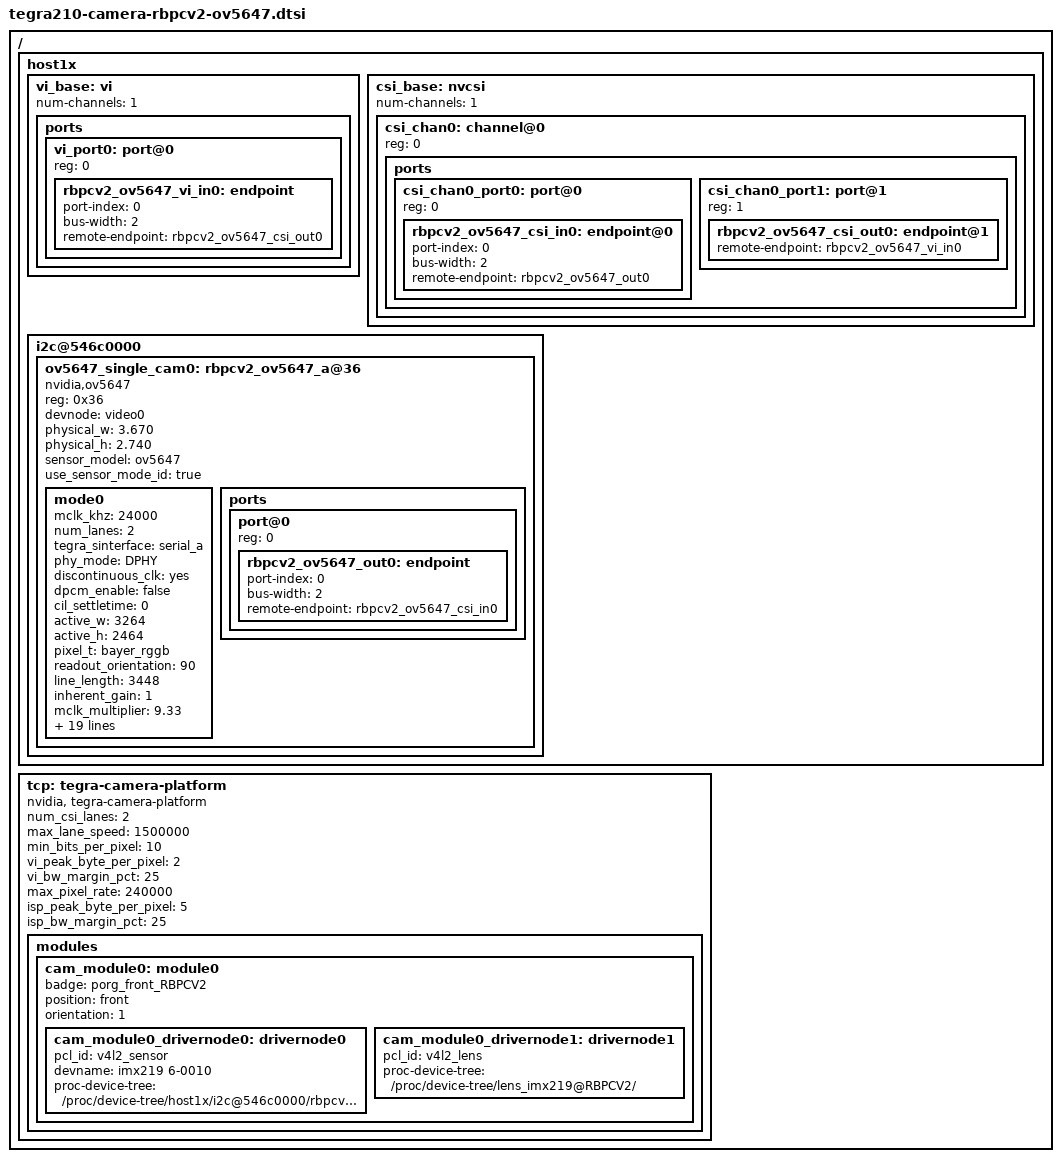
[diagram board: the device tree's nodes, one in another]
#include <dt-bindings/media/camera.h>
#include <dt-bindings/platform/t210/t210.h>

/ {
    host1x {
		vi_base: vi {
			num-channels = <1>;
			ports {
				#address-cells = <1>;
				#size-cells = <0>;
				vi_port0: port@0 {
					reg = <0>;
					rbpcv2_ov5647_vi_in0: endpoint {
						port-index = <0>;
						bus-width = <2>;
						remote-endpoint = <&rbpcv2_ov5647_csi_out0>;
					};
				};
			};
		};        
		csi_base: nvcsi {
			num-channels = <1>;
			#address-cells = <1>;
			#size-cells = <0>;
			csi_chan0: channel@0 {
				reg = <0>;
				ports {
					#address-cells = <1>;
					#size-cells = <0>;
					csi_chan0_port0: port@0 {
						reg = <0>;
						rbpcv2_ov5647_csi_in0: endpoint@0 {
							port-index = <0>;
							bus-width = <2>;
							remote-endpoint = <&rbpcv2_ov5647_out0>;
						};
					};
					csi_chan0_port1: port@1 {
						reg = <1>;
						rbpcv2_ov5647_csi_out0: endpoint@1 {
							remote-endpoint = <&rbpcv2_ov5647_vi_in0>;
						};
					};
				};
			};
		};

        i2c@546c0000 {
            ov5647_single_cam0: rbpcv2_ov5647_a@36 {
                compatible = "nvidia,ov5647";
		
                /* I2C device address */
                reg = <0x36>;

                /* V4L2 device node location */
                devnode = "video0";

                /* Physical dimensions of sensor */
                physical_w = "3.670";
                physical_h = "2.740";
                sensor_model = "ov5647";
                use_sensor_mode_id = "true";
                status = "okay";

				mode0 { /* IMX219_MODE_3264x2464_21FPS */
					mclk_khz = "24000";
					num_lanes = "2";
					tegra_sinterface = "serial_a";
					phy_mode = "DPHY";
					discontinuous_clk = "yes";
					dpcm_enable = "false";
					cil_settletime = "0";

					active_w = "3264";
					active_h = "2464";
					pixel_t = "bayer_rggb";
					readout_orientation = "90";
					line_length = "3448";
					inherent_gain = "1";
					mclk_multiplier = "9.33";
					pix_clk_hz = "182400000";

					gain_factor = "16";
					framerate_factor = "1000000";
					exposure_factor = "1000000";
					min_gain_val = "16"; /* 1.00x */
					max_gain_val = "170"; /* 10.66x */
					step_gain_val = "1";
					default_gain = "16"; /* 1.00x */
					min_hdr_ratio = "1";
					max_hdr_ratio = "1";
					min_framerate = "2000000"; /* 2.0 fps */
					max_framerate = "21000000"; /* 21.0 fps */
					step_framerate = "1";
					default_framerate = "21000000"; /* 21.0 fps */
					min_exp_time = "13"; /* us */
					max_exp_time = "683709"; /* us */
					step_exp_time = "1";
					default_exp_time = "2495"; /* us */

					embedded_metadata_height = "2";
				};				

                ports {
					#address-cells = <1>;
					#size-cells = <0>;

					port@0 {
						reg = <0>;
						rbpcv2_ov5647_out0: endpoint {
							port-index = <0>;
							bus-width = <2>;
							remote-endpoint = <&rbpcv2_ov5647_csi_in0>;
						};
					};
				};
            };
        };
    };
};


/ {
	tcp: tegra-camera-platform {
		compatible = "nvidia, tegra-camera-platform";

		/**
		* Physical settings to calculate max ISO BW
		*
		* num_csi_lanes = <>;
		* Total number of CSI lanes when all cameras are active
		*
		* max_lane_speed = <>;
		* Max lane speed in Kbit/s
		*
		* min_bits_per_pixel = <>;
		* Min bits per pixel
		*
		* vi_peak_byte_per_pixel = <>;
		* Max byte per pixel for the VI ISO case
		*
		* vi_bw_margin_pct = <>;
		* Vi bandwidth margin in percentage
		*
		* max_pixel_rate = <>;
		* Max pixel rate in Kpixel/s for the ISP ISO case
		*
		* isp_peak_byte_per_pixel = <>;
		* Max byte per pixel for the ISP ISO case
		*
		* isp_bw_margin_pct = <>;
		* Isp bandwidth margin in percentage
		*/
		num_csi_lanes = <2>;
		max_lane_speed = <1500000>;
		min_bits_per_pixel = <10>;
		vi_peak_byte_per_pixel = <2>;
		vi_bw_margin_pct = <25>;
		max_pixel_rate = <240000>;
		isp_peak_byte_per_pixel = <5>;
		isp_bw_margin_pct = <25>;

		/**
		 * The general guideline for naming badge_info contains 3 parts, and is as follows,
		 * The first part is the camera_board_id for the module; if the module is in a FFD
		 * platform, then use the platform name for this part.
		 * The second part contains the position of the module, ex. "rear" or "front".
		 * The third part contains the last 6 characters of a part number which is found
		 * in the module's specsheet from the vendor.
		 */
		modules {
			cam_module0: module0 {
				badge = "porg_front_RBPCV2";
				position = "front";
				orientation = "1";
				cam_module0_drivernode0: drivernode0 {
					pcl_id = "v4l2_sensor";
					devname = "imx219 6-0010";
					proc-device-tree = "/proc/device-tree/host1x/i2c@546c0000/rbpcv2_imx219_a@10";
				};
				cam_module0_drivernode1: drivernode1 {
					pcl_id = "v4l2_lens";
					proc-device-tree = "/proc/device-tree/lens_imx219@RBPCV2/";
				};
			};
		};
	};
};
